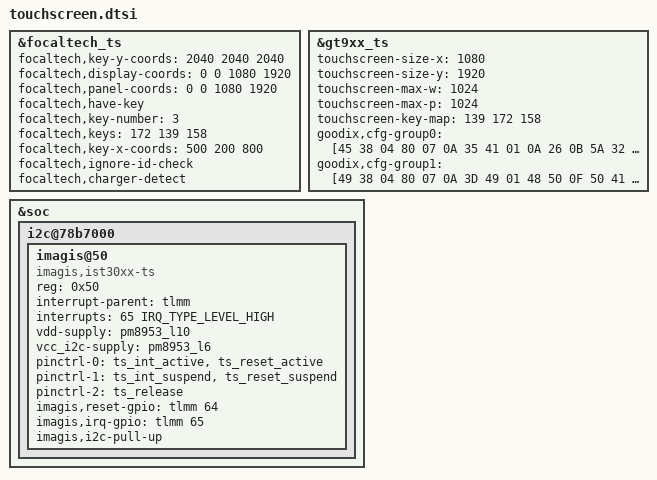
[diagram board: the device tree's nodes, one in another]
&focaltech_ts {
	status = "okay";
	
	focaltech,key-y-coords = <2040 2040 2040>;
	focaltech,display-coords = <0 0 1080 1920>;
	focaltech,panel-coords = <0 0 1080 1920>;
	focaltech,have-key;
	focaltech,key-number = <3>;
	focaltech,keys = <172 139 158>;
	focaltech,key-x-coords = <500 200 800>;
	focaltech,ignore-id-check;
	focaltech,charger-detect;
};

&gt9xx_ts {
	status = "okay";

	touchscreen-size-x = <1080>;
	touchscreen-size-y = <1920>;
	touchscreen-max-w = <1024>;
	touchscreen-max-p = <1024>;
	touchscreen-key-map = <139 172 158>;
	goodix,cfg-group0 = [45 38 04 80 07 0A 35 41 01 0A
					26 0B 5A 32 05 05 00 00 00 00
					00 00 05 14 14 26 14 8C 2E 0E
					4A 4C F4 0A F4 0A 00 BA 33 11
					00 00 00 00 00 05 03 28 78 96
					3A 1E 5A 8F 90 03 00 00 00 04
					CE 21 00 B0 29 28 98 34 00 87
					41 60 7B 51 00 7B 18 38 60 00
					F0 55 40 AA A0 27 00 04 53 00
					00 00 00 00 00 02 00 00 00 00
					00 00 00 00 00 00 3C 00 00 00
					00 28 02 04 06 08 0A 0C 0E 10
					12 14 16 18 1A 1C 00 00 00 00
					00 00 00 00 00 00 00 00 00 00
					00 00 00 02 04 06 08 0A 0C 0F
					10 12 13 14 16 18 1C 1D 1E 1F
					20 21 22 24 26 28 29 2A 00 00
					00 00 00 00 00 00 00 00 00 00
					00 00 00 00 23 01];
	goodix,cfg-group1 = [49 38 04 80 07 0A 3D 49 01 48
					50 0F 50 41 03 65 00 00 00 00
					00 00 0F 16 1A 23 14 87 27 DD
					50 52 E7 07 E7 07 00 42 33 91
					0A 00 00 00 00 83 C4 14 14 C8
					02 3C 64 8F D0 03 05 1E 00 04
					93 3F 00 8A 46 00 82 4D 00 7C
					55 00 76 5F 00 76 18 38 60 00
					F7 55 40 99 99 17 00 00 D1 00
					00 00 00 00 00 02 00 00 05 28
					00 00 00 00 00 28 64 00 00 00
					00 50 0C 0B 0A 09 08 07 06 05
					04 03 02 01 00 0D 0E 0F 10 11
					12 13 14 15 16 17 18 19 1A FF
					FF FF 29 28 24 22 20 1F 1E 0A
					08 06 05 04 02 00 FF FF FF 00
					00 00 00 00 00 00 00 00 28 32
					3C 10 23 28 0F 00 00 00 00 00
					00 00 0F 4B 00 00 00 00 00 00
					1E 50 00 00 00 05 00 00 00 00
					01 14 78 1A 19 3C 28 00 00 00
					00 00 00 00 00 00 00 00 00 00
					00 00 00 00 00 00 83 01];
};


&soc {
	i2c@78b7000 { /* BLSP1 QUP3 */
		imagis@50 {
			compatible = "imagis,ist30xx-ts";
			reg = <0x50>;
			interrupt-parent = <&tlmm>;
			interrupts = <65 IRQ_TYPE_LEVEL_HIGH>;
			vdd-supply = <&pm8953_l10>;
			vcc_i2c-supply = <&pm8953_l6>;
			/* pins used by touchscreen */
			pinctrl-names = "pmx_ts_active","pmx_ts_suspend",
					"pmx_ts_release";
			pinctrl-0 = <&ts_int_active &ts_reset_active>;
			pinctrl-1 = <&ts_int_suspend &ts_reset_suspend>;
			pinctrl-2 = <&ts_release>;
			imagis,reset-gpio = <&tlmm 64 0x0>;
			imagis,irq-gpio = <&tlmm 65 0x2008>;
			imagis,i2c-pull-up;
		};
	};
};
